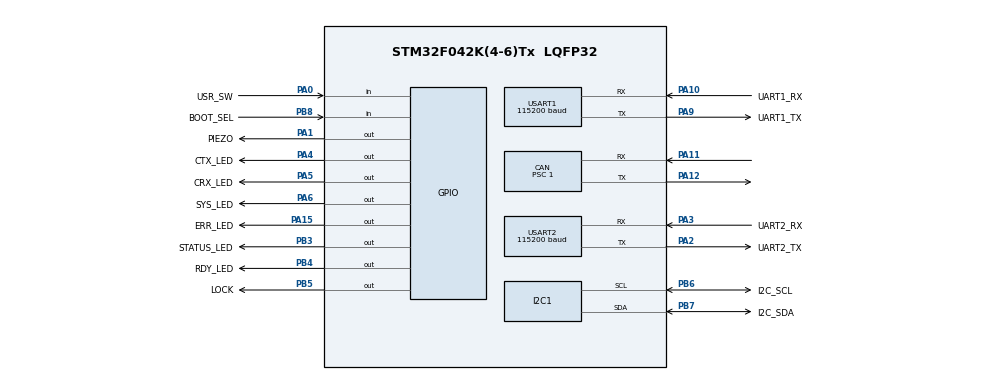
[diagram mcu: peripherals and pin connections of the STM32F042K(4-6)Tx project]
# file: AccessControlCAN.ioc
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CAN.AWUM=ENABLE
CAN.BS1=CAN_BS1_13TQ
CAN.BS2=CAN_BS2_2TQ
CAN.CalculateBaudRate=500000
CAN.CalculateTimeBit=2000
CAN.CalculateTimeQuantum=125.0
CAN.NART=ENABLE
CAN.Prescaler=1
CAN.SJW=CAN_SJW_1TQ
I2C1.Timing=0x00201D2B
Mcu.Family=STM32F0
Mcu.Name=STM32F042K(4-6)Tx
Mcu.Package=LQFP32
NVIC.CEC_CAN_IRQn=true\:0\:0\:false\:false\:true\:true\:true\:true
PA0.GPIO_Label=USR_SW
PA0.Signal=GPIO_Input
PA1.GPIO_Label=PIEZO
PA1.Signal=GPIO_Output
PA10.GPIO_Label=UART1_RX
PA10.Mode=Asynchronous
PA10.Signal=USART1_RX
PA11.Mode=CAN_Activate
PA11.Signal=CAN_RX
PA12.Mode=CAN_Activate
PA12.Signal=CAN_TX
PA13.Mode=Serial_Wire
PA13.Signal=SYS_SWDIO
PA14.Mode=Serial_Wire
PA14.Signal=SYS_SWCLK
PA15.GPIO_Label=ERR_LED
PA15.Signal=GPIO_Output
PA2.GPIO_Label=UART2_TX
PA2.Mode=Asynchronous
PA2.Signal=USART2_TX
PA3.GPIO_Label=UART2_RX
PA3.Mode=Asynchronous
PA3.Signal=USART2_RX
PA4.GPIO_Label=CTX_LED
PA4.Signal=GPIO_Output
PA5.GPIO_Label=CRX_LED
PA5.Signal=GPIO_Output
PA6.GPIO_Label=SYS_LED
PA6.Signal=GPIO_Output
PA9.GPIO_Label=UART1_TX
PA9.Mode=Asynchronous
PA9.Signal=USART1_TX
PB3.GPIO_Label=STATUS_LED
PB3.Signal=GPIO_Output
PB4.GPIO_Label=RDY_LED
PB4.Signal=GPIO_Output
PB5.GPIO_Label=LOCK
PB5.Signal=GPIO_Output
PB6.GPIO_Label=I2C_SCL
PB6.Mode=I2C
PB6.Signal=I2C1_SCL
PB7.GPIO_Label=I2C_SDA
PB7.Mode=I2C
PB7.Signal=I2C1_SDA
PB8.GPIO_Label=BOOT_SEL
PB8.Signal=GPIO_Input
PF0-OSC_IN.GPIO_Label=XTAL0
PF0-OSC_IN.Mode=HSE-External-Oscillator
PF0-OSC_IN.Signal=RCC_OSC_IN
PF1-OSC_OUT.GPIO_Label=XTAL1
PF1-OSC_OUT.Mode=HSE-External-Oscillator
PF1-OSC_OUT.Signal=RCC_OSC_OUT
ProjectManager.HeapSize=0x200
ProjectManager.StackSize=0x400
ProjectManager.TargetToolchain=STM32CubeIDE
USART1.BaudRate=115200
USART1.VirtualMode-Asynchronous=VM_ASYNC
USART2.BaudRate=115200
USART2.VirtualMode-Asynchronous=VM_ASYNC
board=custom

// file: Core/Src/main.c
/* USER CODE BEGIN Header */
/**
  ******************************************************************************
  * @file           : main.c
  * @brief          : Main program body
  ******************************************************************************
  * @attention
  *
  * Copyright (c) 2026 STMicroelectronics.
  * All rights reserved.
  *
  * This software is licensed under terms that can be found in the LICENSE file
  * in the root directory of this software component.
  * If no LICENSE file comes with this software, it is provided AS-IS.
  *
  ******************************************************************************
  */
/* USER CODE END Header */
#include "main.h"

/* USER CODE BEGIN Includes */
#include "can_manager.h"
#include "pn532.h"

/* USER CODE END Includes */

CAN_HandleTypeDef hcan;

I2C_HandleTypeDef hi2c1;

UART_HandleTypeDef huart1;
UART_HandleTypeDef huart2;

/* USER CODE BEGIN PV */

// TODO: change this if you have multiple doors on the same CAN bus, each door should have a unique ID
uint32_t my_door_id = 0x123; // The unique ID of this door, used as the CAN message ID for access requests

/* USER CODE END PV */

void SystemClock_Config(void);
static void MX_GPIO_Init(void);
static void MX_CAN_Init(void);
static void MX_I2C1_Init(void);
static void MX_USART1_UART_Init(void);
static void MX_USART2_UART_Init(void);
/* USER CODE BEGIN PFP */
void open_the_door(void);
/* USER CODE END PFP */

int main(void)
{

  /* MCU Configuration--------------------------------------------------------*/

  /* Reset of all peripherals, Initializes the Flash interface and the Systick. */
  HAL_Init();

  /* Configure the system clock */
  SystemClock_Config();

  /* Initialize all configured peripherals */
  MX_GPIO_Init();
  MX_CAN_Init();
  MX_I2C1_Init();
  MX_USART1_UART_Init();
  MX_USART2_UART_Init();
  /* USER CODE BEGIN 2 */

  CAN_Manager_Init();

  HAL_Delay(1000);

  // reset the lock at startup
  HAL_GPIO_WritePin(LOCK_GPIO_Port, LOCK_Pin, GPIO_PIN_RESET);

  if (!PN532_Init()) {
	  // error led if init fail
	  HAL_GPIO_WritePin(ERR_LED_GPIO_Port, ERR_LED_Pin, GPIO_PIN_SET);
  }

  // ToDO : remove after the demo
  uint8_t demo_flag = 0;

  /* USER CODE END 2 */

  /* Infinite loop */
  /* USER CODE BEGIN WHILE */
  while (1)
  {

	  // if a CAN message has been received and the door should be opened, we trigger the opening sequence
	  if (open_door_flag)
	  {
		  // open the door and reset the flag
		  open_door_flag = 0;
		  open_the_door();
	  }
	  // if a CAN message has been received and the access is denied, we trigger an error led
	  if (not_ok_flag)
	  {
		  // access denied, we can trigger an error led or buzzer
		  not_ok_flag = 0;
		  HAL_GPIO_WritePin(ERR_LED_GPIO_Port, ERR_LED_Pin, GPIO_PIN_SET);
		  HAL_Delay(3000);
		  HAL_GPIO_WritePin(ERR_LED_GPIO_Port, ERR_LED_Pin, GPIO_PIN_RESET);
	  }

	  HAL_Delay(50);

	  // ToDO : remove after the demo
	  /* CODE USED ONLY FOR THE DEMO BECAUSE PN532 DONT WAKE UP */
	  /* Alternate sending requests that will be validated by the server side and requests that will be denieded  */

	  HAL_GPIO_WritePin(ERR_LED_GPIO_Port, ERR_LED_Pin, GPIO_PIN_RESET);

	  uint8_t mock_uid_ok[7] = {0x01, 0x02, 0x03, 0x04, 0x05, 0x06, 0x07};
	  uint8_t mock_uid_ok_len = 7;

	  uint8_t mock_uid_notok[7] = {0xAA, 0xBB, 0xCC, 0xDD, 0xEE, 0xFF, 0xAA};
	  uint8_t mock_uid_notok_len = 7;

	  if (demo_flag == 0 ){
		  // send a request that will be validated
		  CAN_SendAccessRequest(my_door_id, REQ_DOOR_SEND, mock_uid_ok, mock_uid_ok_len);
		  demo_flag = 1;
	  } else{
		  demo_flag = 0;
		  // send a request that will be denied
		  CAN_SendAccessRequest(my_door_id, REQ_DOOR_SEND, mock_uid_notok, mock_uid_notok_len);
	  }
	  HAL_Delay(5000);
	  /* End of demo code to remove */

    /* USER CODE END WHILE */

  }
}

void SystemClock_Config(void)
{
  RCC_OscInitTypeDef RCC_OscInitStruct = {0};
  RCC_ClkInitTypeDef RCC_ClkInitStruct = {0};
  RCC_PeriphCLKInitTypeDef PeriphClkInit = {0};

  /** Initializes the RCC Oscillators according to the specified parameters
  * in the RCC_OscInitTypeDef structure.
  */
  RCC_OscInitStruct.OscillatorType = RCC_OSCILLATORTYPE_HSI;
  RCC_OscInitStruct.HSIState = RCC_HSI_ON;
  RCC_OscInitStruct.HSICalibrationValue = RCC_HSICALIBRATION_DEFAULT;
  RCC_OscInitStruct.PLL.PLLState = RCC_PLL_NONE;
  if (HAL_RCC_OscConfig(&RCC_OscInitStruct) != HAL_OK)
  {
    Error_Handler();
  }

  /** Initializes the CPU, AHB and APB buses clocks
  */
  RCC_ClkInitStruct.ClockType = RCC_CLOCKTYPE_HCLK|RCC_CLOCKTYPE_SYSCLK
                              |RCC_CLOCKTYPE_PCLK1;
  RCC_ClkInitStruct.SYSCLKSource = RCC_SYSCLKSOURCE_HSI;
  RCC_ClkInitStruct.AHBCLKDivider = RCC_SYSCLK_DIV1;
  RCC_ClkInitStruct.APB1CLKDivider = RCC_HCLK_DIV1;

  if (HAL_RCC_ClockConfig(&RCC_ClkInitStruct, FLASH_LATENCY_0) != HAL_OK)
  {
    Error_Handler();
  }
  PeriphClkInit.PeriphClockSelection = RCC_PERIPHCLK_USART1|RCC_PERIPHCLK_I2C1;
  PeriphClkInit.Usart1ClockSelection = RCC_USART1CLKSOURCE_PCLK1;
  PeriphClkInit.I2c1ClockSelection = RCC_I2C1CLKSOURCE_HSI;
  if (HAL_RCCEx_PeriphCLKConfig(&PeriphClkInit) != HAL_OK)
  {
    Error_Handler();
  }
}

static void MX_CAN_Init(void)
{

  hcan.Instance = CAN;
  hcan.Init.Prescaler = 1;
  hcan.Init.Mode = CAN_MODE_NORMAL;
  hcan.Init.SyncJumpWidth = CAN_SJW_1TQ;
  hcan.Init.TimeSeg1 = CAN_BS1_13TQ;
  hcan.Init.TimeSeg2 = CAN_BS2_2TQ;
  hcan.Init.TimeTriggeredMode = DISABLE;
  hcan.Init.AutoBusOff = DISABLE;
  hcan.Init.AutoWakeUp = ENABLE;
  hcan.Init.AutoRetransmission = ENABLE;
  hcan.Init.ReceiveFifoLocked = DISABLE;
  hcan.Init.TransmitFifoPriority = DISABLE;
  if (HAL_CAN_Init(&hcan) != HAL_OK)
  {
    Error_Handler();
  }

}

static void MX_I2C1_Init(void)
{

  hi2c1.Instance = I2C1;
  hi2c1.Init.Timing = 0x00201D2B;
  hi2c1.Init.OwnAddress1 = 0;
  hi2c1.Init.AddressingMode = I2C_ADDRESSINGMODE_7BIT;
  hi2c1.Init.DualAddressMode = I2C_DUALADDRESS_DISABLE;
  hi2c1.Init.OwnAddress2 = 0;
  hi2c1.Init.OwnAddress2Masks = I2C_OA2_NOMASK;
  hi2c1.Init.GeneralCallMode = I2C_GENERALCALL_DISABLE;
  hi2c1.Init.NoStretchMode = I2C_NOSTRETCH_DISABLE;
  if (HAL_I2C_Init(&hi2c1) != HAL_OK)
  {
    Error_Handler();
  }

  /** Configure Analogue filter
  */
  if (HAL_I2CEx_ConfigAnalogFilter(&hi2c1, I2C_ANALOGFILTER_ENABLE) != HAL_OK)
  {
    Error_Handler();
  }

  /** Configure Digital filter
  */
  if (HAL_I2CEx_ConfigDigitalFilter(&hi2c1, 0) != HAL_OK)
  {
    Error_Handler();
  }

}

static void MX_USART1_UART_Init(void)
{

  huart1.Instance = USART1;
  huart1.Init.BaudRate = 115200;
  huart1.Init.WordLength = UART_WORDLENGTH_8B;
  huart1.Init.StopBits = UART_STOPBITS_1;
  huart1.Init.Parity = UART_PARITY_NONE;
  huart1.Init.Mode = UART_MODE_TX_RX;
  huart1.Init.HwFlowCtl = UART_HWCONTROL_NONE;
  huart1.Init.OverSampling = UART_OVERSAMPLING_16;
  huart1.Init.OneBitSampling = UART_ONE_BIT_SAMPLE_DISABLE;
  huart1.AdvancedInit.AdvFeatureInit = UART_ADVFEATURE_NO_INIT;
  if (HAL_UART_Init(&huart1) != HAL_OK)
  {
    Error_Handler();
  }

}

static void MX_USART2_UART_Init(void)
{

  huart2.Instance = USART2;
  huart2.Init.BaudRate = 115200;
  huart2.Init.WordLength = UART_WORDLENGTH_8B;
  huart2.Init.StopBits = UART_STOPBITS_1;
  huart2.Init.Parity = UART_PARITY_NONE;
  huart2.Init.Mode = UART_MODE_TX_RX;
  huart2.Init.HwFlowCtl = UART_HWCONTROL_NONE;
  huart2.Init.OverSampling = UART_OVERSAMPLING_16;
  huart2.Init.OneBitSampling = UART_ONE_BIT_SAMPLE_DISABLE;
  huart2.AdvancedInit.AdvFeatureInit = UART_ADVFEATURE_NO_INIT;
  if (HAL_UART_Init(&huart2) != HAL_OK)
  {
    Error_Handler();
  }

}

static void MX_GPIO_Init(void)
{
  GPIO_InitTypeDef GPIO_InitStruct = {0};

  /* GPIO Ports Clock Enable */
  __HAL_RCC_GPIOF_CLK_ENABLE();
  __HAL_RCC_GPIOA_CLK_ENABLE();
  __HAL_RCC_GPIOB_CLK_ENABLE();

  /*Configure GPIO pin Output Level */
  HAL_GPIO_WritePin(GPIOA, PIEZO_Pin|CTX_LED_Pin|CRX_LED_Pin|SYS_LED_Pin
                          |ERR_LED_Pin, GPIO_PIN_RESET);

  /*Configure GPIO pin Output Level */
  HAL_GPIO_WritePin(GPIOA, PN532_RST_Pin, GPIO_PIN_RESET);
  HAL_GPIO_WritePin(GPIOB, STATUS_LED_Pin|RDY_LED_Pin|LOCK_Pin, GPIO_PIN_RESET);

  /*Configure GPIO pin : USR_SW_Pin */
  GPIO_InitStruct.Pin = USR_SW_Pin;
  GPIO_InitStruct.Mode = GPIO_MODE_INPUT;
  GPIO_InitStruct.Pull = GPIO_NOPULL;
  HAL_GPIO_Init(USR_SW_GPIO_Port, &GPIO_InitStruct);

  /*Configure GPIO pins : PIEZO_Pin CTX_LED_Pin CRX_LED_Pin SYS_LED_Pin
                           ERR_LED_Pin PN532_RST_Pin */
  GPIO_InitStruct.Pin = PIEZO_Pin|CTX_LED_Pin|CRX_LED_Pin|SYS_LED_Pin
                          |ERR_LED_Pin|PN532_RST_Pin;
  GPIO_InitStruct.Mode = GPIO_MODE_OUTPUT_PP;
  GPIO_InitStruct.Pull = GPIO_NOPULL;
  GPIO_InitStruct.Speed = GPIO_SPEED_FREQ_LOW;
  HAL_GPIO_Init(GPIOA, &GPIO_InitStruct);

  /*Configure GPIO pins : STATUS_LED_Pin RDY_LED_Pin LOCK_Pin */
  GPIO_InitStruct.Pin = STATUS_LED_Pin|RDY_LED_Pin|LOCK_Pin;
  GPIO_InitStruct.Mode = GPIO_MODE_OUTPUT_PP;
  GPIO_InitStruct.Pull = GPIO_NOPULL;
  GPIO_InitStruct.Speed = GPIO_SPEED_FREQ_LOW;
  HAL_GPIO_Init(GPIOB, &GPIO_InitStruct);

  /*Configure GPIO pin : BOOT_SEL_Pin */
  GPIO_InitStruct.Pin = BOOT_SEL_Pin;
  GPIO_InitStruct.Mode = GPIO_MODE_INPUT;
  GPIO_InitStruct.Pull = GPIO_NOPULL;
  HAL_GPIO_Init(BOOT_SEL_GPIO_Port, &GPIO_InitStruct);

}

/* USER CODE BEGIN 4 */

// A simple delay function for microseconds using a busy-wait loop
static void delay_us(uint32_t us)
{
	us = us * 1;
	while (us--) {
		__NOP();
	}
}

// Function to open the door: activate the lock, sound the buzzer, and then deactivate the lock
void open_the_door(void)
{
    // toggle the lock pin to open the door
    HAL_GPIO_WritePin(LOCK_GPIO_Port, LOCK_Pin, GPIO_PIN_SET);

    // activate the buzzer for 3 seconds at 2 kHz
    uint32_t start_tick = HAL_GetTick();

    while ((HAL_GetTick() - start_tick) < 3000)
    {
        HAL_GPIO_TogglePin(PIEZO_GPIO_Port, PIEZO_Pin);
        delay_us(250); // 250 µs High + 250 µs Low = 500 µs période = 2 kHz
    }

    // stop the buzzer
    HAL_GPIO_WritePin(PIEZO_GPIO_Port, PIEZO_Pin, GPIO_PIN_RESET);

    // deactivate the lock after 3 seconds
    HAL_GPIO_WritePin(LOCK_GPIO_Port, LOCK_Pin, GPIO_PIN_RESET);
}

/* USER CODE END 4 */

void Error_Handler(void)
{
  __disable_irq();
  while (1)
  {
  }
}
